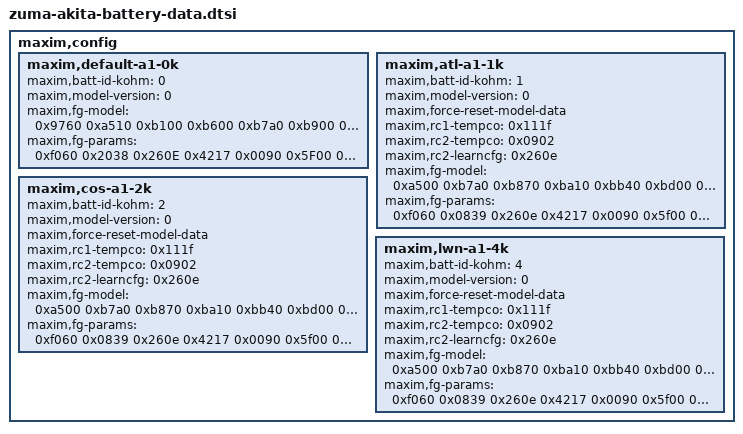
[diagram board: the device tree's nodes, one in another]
// SPDX-License-Identifier: GPL-2.0-only
/*
 * Battery device tree entries
 *
 * Copyright 2022 Google LLC
 *
 */

maxim,config {

	/* R4_p1_gen.ini, 2021-01-21, b/174787673, generic model */
	maxim,default-a1-0k {
		maxim,batt-id-kohm = <0>;
		maxim,model-version = <0>;
		maxim,fg-model = /bits/ 16 <
			0x9760 0xa510 0xb100 0xb600 0xb7a0 0xb900 0xba70 0xbc70
			0xbde0 0xbfc0 0xc250 0xc510 0xc990 0xcea0 0xd040 0xd750
			0x0060 0x0120 0x0200 0x0710 0x0e80 0x0df0 0x1430 0x1bd0
			0x1520 0x0d70 0x0950 0x08e0 0x0800 0x0780 0x06b0 0x01e0
			0x0100 0x0100 0x0100 0x0100 0x0100 0x0100 0x0100 0x0100
			0x0100 0x0100 0x0100 0x0100 0x0100 0x0100 0x0100 0x0100
		>;
		maxim,fg-params = /bits/ 16 <
			/* 0x0036 */	0xf060	/* IAvgEmpty */
			/* 0x002a */	0x2038	/* RelaxCFG */
			/* 0x0028 */	0x260E	/* LearnCFG */
			/* 0x001D */	0x4217	/* Config */
			/* 0x00BB */	0x0090	/* Config2 */
			/* 0x0013 */	0x5F00	/* FullSOCthr */
			/* 0x0035 */	0x0994	/* FullCAPRep */
			/* 0x0018 */	0x0994	/* DesignCap */
			/* 0x0046 */	0x0c80	/* dPacc */
			/* 0x0045 */	0x0099	/* dQacc */
			/* 0x0023 */	0x0994	/* FullCAPNom */
			/* 0x003A */	0xA561	/* V_empty */
			/* 0x0012 */	0x1100	/* QResidual00 */
			/* 0x0022 */	0x0800	/* QResidual10 */
			/* 0x0032 */	0x0301	/* QResidual20 */
			/* 0x0042 */	0x0302	/* QResidual30 */
			/* 0x0038 */	0x0700	/* RCOMP0 */
			/* 0x0039 */	0x223E	/* TempCo */
			/* 0x001E */	0x0310	/* ICHGTerm */
			/* 0x002C */	0xED51	/* TGain */
			/* 0x002D */	0x1EBA	/* TOff */
			/* 0x00B9 */	0x0014	/* Curve */
			/* 0x002B */	0x3870	/* MiscCFG */
			/* 0x0004 */	0x0000	/* AtRate */
			/* 0x0049 */	0x2241	/* convgcfg */
			/* 0x0029 */	0xc623	/* FilterCFG */
			/* 0x003c */	0x2D00	/* TaskPeriod */
		>;
	};

	/* 1_ATL_031522_RC2_INI_0830.txt http://b/244371981#comment1 */
	maxim,atl-a1-1k {
		maxim,batt-id-kohm = <1>;
		maxim,model-version = <0>;
		maxim,force-reset-model-data;
		maxim,rc1-tempco = /bits/ 16 <0x111f>;
		maxim,rc2-tempco = /bits/ 16 <0x0902>;
		maxim,rc2-learncfg = /bits/ 16 <0x260e>;
		maxim,fg-model = /bits/ 16 <
			0xa500 0xb7a0 0xb870 0xba10 0xbb40 0xbd00 0xbe40 0xbfe0
			0xc230 0xc430 0xc720 0xca00 0xcdc0 0xd180 0xd5d0 0xdd90
			0x01b0 0x1600 0x0c00 0x0d00 0x1700 0x1300 0x1200 0x0f20
			0x07d0 0x07f0 0x0810 0x06e0 0x06f0 0x07f0 0x04f0 0x04f0
			0x0200 0x0200 0x0200 0x0200 0x0200 0x0200 0x0200 0x0200
			0x0200 0x0200 0x0200 0x0200 0x0200 0x0200 0x0200 0x0200
		>;
		maxim,fg-params = /bits/ 16 <
			/* 0x0036 */	0xf060	/* nIAvgEmpty -> IAvgEmpty */
			/* 0x002a */	0x0839	/* nRelaxCFG -> RelaxCFG */
			/* 0x0028 */	0x260e	/* nLearnCFG -> LearnCFG */
			/* 0x001D */	0x4217	/* Config: */
			/* 0x00BB */	0x0090	/* Config2: OCVQen|DSOCIi */
			/* 0x0013 */	0x5f00	/* nFullSOCThr -> FullSOCThr*/
			/* 0x0035 */	0x088d	/* nFullCapRep */
			/* 0x0018 */	0x088d	/* nDesignCap */
			/* 0x0046 */	0x3200	/* dPacc */
			/* 0x0045 */	0x0223	/* dQacc */
			/* 0x0023 */	0x088d	/* nFullCapNom */
			/* 0x003A */	0xA561	/* V_empty */
			/* 0x0012 */	0x1680	/* nQRTable00 -> QResidual00 */
			/* 0x0022 */	0x0b80	/* nQRTable10 -> QResidual10 */
			/* 0x0032 */	0x0680	/* nQRTable20 -> QResidual20 */
			/* 0x0042 */	0x0500	/* nQRTable30 -> QResidual30 */
			/* 0x0038 */	0x0460	/* nRcomp0 */
			/* 0x0039 */	0x0902	/* nTempco */
			/* 0x001E */	0x0560	/* ICHGTerm */
			/* 0x002C */	0xED51	/* *TGain */
			/* 0x002D */	0x1EBA	/* *TOFF */
			/* 0x00B9 */	0x0014	/* *TCurve */
			/* 0x002B */	0x3870	/* *nMiscCfg */
			/* 0x0004 */	0x1900	/* AtRate @ 0x04 */
			/* 0x0049 */	0x2241	/* convgcfg */
			/* 0x0029 */	0xc613	/* FilterCFG */
			/* 0x003c */	0x2D00	/* TaskPeriod */
			/* 0x002e */	0x0400	/* CGain */
		>;
	};

        /* COS: 1_ATL_031522_RC2_INI_0830.txt http://b/244371981#comment1 */
	maxim,cos-a1-2k {
		maxim,batt-id-kohm = <2>;
		maxim,model-version = <0>;
		maxim,force-reset-model-data;
		maxim,rc1-tempco = /bits/ 16 <0x111f>;
		maxim,rc2-tempco = /bits/ 16 <0x0902>;
		maxim,rc2-learncfg = /bits/ 16 <0x260e>;
		maxim,fg-model = /bits/ 16 <
			0xa500 0xb7a0 0xb870 0xba10 0xbb40 0xbd00 0xbe40 0xbfe0
			0xc230 0xc430 0xc720 0xca00 0xcdc0 0xd180 0xd5d0 0xdd90
			0x01b0 0x1600 0x0c00 0x0d00 0x1700 0x1300 0x1200 0x0f20
			0x07d0 0x07f0 0x0810 0x06e0 0x06f0 0x07f0 0x04f0 0x04f0
			0x0200 0x0200 0x0200 0x0200 0x0200 0x0200 0x0200 0x0200
			0x0200 0x0200 0x0200 0x0200 0x0200 0x0200 0x0200 0x0200
		>;
		maxim,fg-params = /bits/ 16 <
			/* 0x0036 */	0xf060	/* nIAvgEmpty -> IAvgEmpty */
			/* 0x002a */	0x0839	/* nRelaxCFG -> RelaxCFG */
			/* 0x0028 */	0x260e	/* nLearnCFG -> LearnCFG */
			/* 0x001D */	0x4217	/* Config: */
			/* 0x00BB */	0x0090	/* Config2: OCVQen|DSOCIi */
			/* 0x0013 */	0x5f00	/* nFullSOCThr -> FullSOCThr*/
			/* 0x0035 */	0x088d	/* nFullCapRep */
			/* 0x0018 */	0x088d	/* nDesignCap */
			/* 0x0046 */	0x3200	/* dPacc */
			/* 0x0045 */	0x0223	/* dQacc */
			/* 0x0023 */	0x088d	/* nFullCapNom */
			/* 0x003A */	0xA561	/* V_empty */
			/* 0x0012 */	0x1680	/* nQRTable00 -> QResidual00 */
			/* 0x0022 */	0x0b80	/* nQRTable10 -> QResidual10 */
			/* 0x0032 */	0x0680	/* nQRTable20 -> QResidual20 */
			/* 0x0042 */	0x0500	/* nQRTable30 -> QResidual30 */
			/* 0x0038 */	0x0460	/* nRcomp0 */
			/* 0x0039 */	0x0902	/* nTempco */
			/* 0x001E */	0x0560	/* ICHGTerm */
			/* 0x002C */	0xED51	/* *TGain */
			/* 0x002D */	0x1EBA	/* *TOFF */
			/* 0x00B9 */	0x0014	/* *TCurve */
			/* 0x002B */	0x3870	/* *nMiscCfg */
			/* 0x0004 */	0x1900	/* AtRate @ 0x04 */
			/* 0x0049 */	0x2241	/* convgcfg */
			/* 0x0029 */	0xc613	/* FilterCFG */
			/* 0x003c */	0x2D00	/* TaskPeriod */
			/* 0x002e */	0x0400	/* CGain */
		>;
	};

	/* LSN: 1_ATL_031522_RC2_INI_0830.txt http://b/244371981#comment1 */
	maxim,lwn-a1-4k {
		maxim,batt-id-kohm = <4>;
		maxim,model-version = <0>;
		maxim,force-reset-model-data;
		maxim,rc1-tempco = /bits/ 16 <0x111f>;
		maxim,rc2-tempco = /bits/ 16 <0x0902>;
		maxim,rc2-learncfg = /bits/ 16 <0x260e>;
		maxim,fg-model = /bits/ 16 <
			0xa500 0xb7a0 0xb870 0xba10 0xbb40 0xbd00 0xbe40 0xbfe0
			0xc230 0xc430 0xc720 0xca00 0xcdc0 0xd180 0xd5d0 0xdd90
			0x01b0 0x1600 0x0c00 0x0d00 0x1700 0x1300 0x1200 0x0f20
			0x07d0 0x07f0 0x0810 0x06e0 0x06f0 0x07f0 0x04f0 0x04f0
			0x0200 0x0200 0x0200 0x0200 0x0200 0x0200 0x0200 0x0200
			0x0200 0x0200 0x0200 0x0200 0x0200 0x0200 0x0200 0x0200
		>;
		maxim,fg-params = /bits/ 16 <
			/* 0x0036 */	0xf060	/* nIAvgEmpty -> IAvgEmpty */
			/* 0x002a */	0x0839	/* nRelaxCFG -> RelaxCFG */
			/* 0x0028 */	0x260e	/* nLearnCFG -> LearnCFG */
			/* 0x001D */	0x4217	/* Config: */
			/* 0x00BB */	0x0090	/* Config2: OCVQen|DSOCIi */
			/* 0x0013 */	0x5f00	/* nFullSOCThr -> FullSOCThr*/
			/* 0x0035 */	0x088d	/* nFullCapRep */
			/* 0x0018 */	0x088d	/* nDesignCap */
			/* 0x0046 */	0x3200	/* dPacc */
			/* 0x0045 */	0x0223	/* dQacc */
			/* 0x0023 */	0x088d	/* nFullCapNom */
			/* 0x003A */	0xA561	/* V_empty */
			/* 0x0012 */	0x1680	/* nQRTable00 -> QResidual00 */
			/* 0x0022 */	0x0b80	/* nQRTable10 -> QResidual10 */
			/* 0x0032 */	0x0680	/* nQRTable20 -> QResidual20 */
			/* 0x0042 */	0x0500	/* nQRTable30 -> QResidual30 */
			/* 0x0038 */	0x0460	/* nRcomp0 */
			/* 0x0039 */	0x0902	/* nTempco */
			/* 0x001E */	0x0560	/* ICHGTerm */
			/* 0x002C */	0xED51	/* *TGain */
			/* 0x002D */	0x1EBA	/* *TOFF */
			/* 0x00B9 */	0x0014	/* *TCurve */
			/* 0x002B */	0x3870	/* *nMiscCfg */
			/* 0x0004 */	0x1900	/* AtRate @ 0x04 */
			/* 0x0049 */	0x2241	/* convgcfg */
			/* 0x0029 */	0xc613	/* FilterCFG */
			/* 0x003c */	0x2D00	/* TaskPeriod */
			/* 0x002e */	0x0400	/* CGain */
		>;
	};
};
